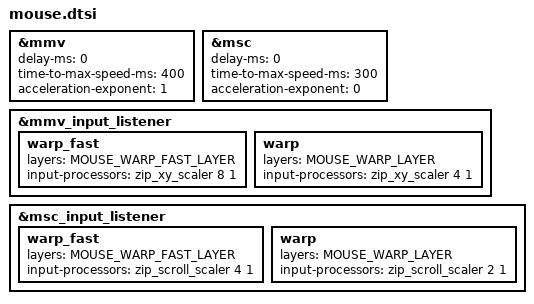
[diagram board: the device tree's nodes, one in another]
/*
 * Mouse / pointing for Mriya — upstream ZMK pointing API.
 *
 * Include AFTER MOUSE_WARP_* are #defined.
 *
 * On mouse layer (left hand holds, right hand moves):
 *   default = fine (former D / ½ of old base)
 *   F = warp mid (~4x)
 *   D = warp fast (~8x)
 */

#define ZMK_POINTING_DEFAULT_MOVE_VAL 600
#define ZMK_POINTING_DEFAULT_SCRL_VAL 12

#include <dt-bindings/zmk/pointing.h>
#include <input/processors.dtsi>
#include <zephyr/dt-bindings/input/input-event-codes.h>

&mmv {
    delay-ms = <0>;
    time-to-max-speed-ms = <400>;
    acceleration-exponent = <1>;
};

&msc {
    delay-ms = <0>;
    time-to-max-speed-ms = <300>;
    acceleration-exponent = <0>;
};

/* First matching override wins — list faster warps before slower ones. */
&mmv_input_listener {
    warp_fast {
        layers = <MOUSE_WARP_FAST_LAYER>;
        input-processors = <&zip_xy_scaler 8 1>;
    };
    warp {
        layers = <MOUSE_WARP_LAYER>;
        input-processors = <&zip_xy_scaler 4 1>;
    };
};

&msc_input_listener {
    warp_fast {
        layers = <MOUSE_WARP_FAST_LAYER>;
        input-processors = <&zip_scroll_scaler 4 1>;
    };
    warp {
        layers = <MOUSE_WARP_LAYER>;
        input-processors = <&zip_scroll_scaler 2 1>;
    };
};
